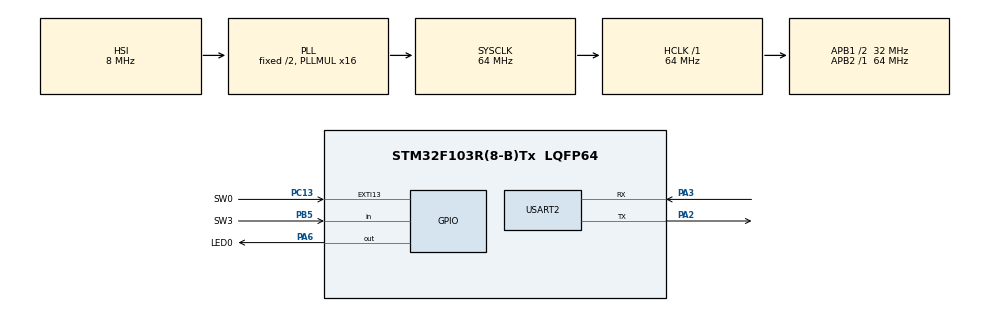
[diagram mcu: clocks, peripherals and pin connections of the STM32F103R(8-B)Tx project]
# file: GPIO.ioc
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Mcu.Family=STM32F1
Mcu.Name=STM32F103R(8-B)Tx
Mcu.Package=LQFP64
NVIC.EXTI15_10_IRQn=true\:0\:0\:false\:false\:true\:true\:true
NVIC.PriorityGroup=NVIC_PRIORITYGROUP_4
PA13.Mode=Serial_Wire
PA13.Signal=SYS_JTMS-SWDIO
PA14.Mode=Serial_Wire
PA14.Signal=SYS_JTCK-SWCLK
PA2.Mode=Asynchronous
PA2.Signal=USART2_TX
PA3.Mode=Asynchronous
PA3.Signal=USART2_RX
PA6.GPIO_Label=LED0
PA6.PinState=GPIO_PIN_RESET
PA6.Signal=GPIO_Output
PB5.GPIO_Label=SW3
PB5.Signal=GPIO_Input
PC13-TAMPER-RTC.GPIO_Label=SW0
PC13-TAMPER-RTC.GPIO_ModeDefaultEXTI=GPIO_MODE_IT_RISING_FALLING
PC13-TAMPER-RTC.Signal=GPXTI13
ProjectManager.HeapSize=0x200
ProjectManager.StackSize=0x400
ProjectManager.TargetToolchain=STM32CubeIDE
RCC.AHBFreq_Value=64000000
RCC.APB1CLKDivider=RCC_HCLK_DIV2
RCC.APB1Freq_Value=32000000
RCC.APB1TimFreq_Value=64000000
RCC.APB2Freq_Value=64000000
RCC.APB2TimFreq_Value=64000000
RCC.HCLKFreq_Value=64000000
RCC.PLLMUL=RCC_PLL_MUL16
RCC.SYSCLKFreq_VALUE=64000000
RCC.SYSCLKSource=RCC_SYSCLKSOURCE_PLLCLK
RCC.USBFreq_Value=64000000
USART2.VirtualMode=VM_ASYNC
board=custom

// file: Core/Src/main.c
/* USER CODE BEGIN Header */
/**
  ******************************************************************************
  * @file           : main.c
  * @brief          : Main program body
  ******************************************************************************
  * @attention
  *
  * <h2><center>&copy; Copyright (c) 2021 STMicroelectronics.
  * All rights reserved.</center></h2>
  *
  * This software component is licensed by ST under BSD 3-Clause license,
  * the "License"; You may not use this file except in compliance with the
  * License. You may obtain a copy of the License at:
  *                        opensource.org/licenses/BSD-3-Clause
  *
  ******************************************************************************
  */
/* USER CODE END Header */
#include "main.h"

UART_HandleTypeDef huart2;

void SystemClock_Config(void);
static void MX_GPIO_Init(void);
static void MX_USART2_UART_Init(void);

int main(void)
{

  /* MCU Configuration--------------------------------------------------------*/

  /* Reset of all peripherals, Initializes the Flash interface and the Systick. */
  HAL_Init();

  /* Configure the system clock */
  SystemClock_Config();

  /* Initialize all configured peripherals */
  MX_GPIO_Init();
  MX_USART2_UART_Init();

  /* Infinite loop */
  /* USER CODE BEGIN WHILE */
  while (1)
  {
	  //HAL_GPIO_WritePin (LED0_GPIO_Port, LED0_Pin, GPIO_PIN_SET);
/*

*/
    /* USER CODE END WHILE */

  }
}

void SystemClock_Config(void)
{
  RCC_OscInitTypeDef RCC_OscInitStruct = {0};
  RCC_ClkInitTypeDef RCC_ClkInitStruct = {0};

  /** Initializes the RCC Oscillators according to the specified parameters
  * in the RCC_OscInitTypeDef structure.
  */
  RCC_OscInitStruct.OscillatorType = RCC_OSCILLATORTYPE_HSI;
  RCC_OscInitStruct.HSIState = RCC_HSI_ON;
  RCC_OscInitStruct.HSICalibrationValue = RCC_HSICALIBRATION_DEFAULT;
  RCC_OscInitStruct.PLL.PLLState = RCC_PLL_ON;
  RCC_OscInitStruct.PLL.PLLSource = RCC_PLLSOURCE_HSI_DIV2;
  RCC_OscInitStruct.PLL.PLLMUL = RCC_PLL_MUL16;
  if (HAL_RCC_OscConfig(&RCC_OscInitStruct) != HAL_OK)
  {
    Error_Handler();
  }
  /** Initializes the CPU, AHB and APB buses clocks
  */
  RCC_ClkInitStruct.ClockType = RCC_CLOCKTYPE_HCLK|RCC_CLOCKTYPE_SYSCLK
                              |RCC_CLOCKTYPE_PCLK1|RCC_CLOCKTYPE_PCLK2;
  RCC_ClkInitStruct.SYSCLKSource = RCC_SYSCLKSOURCE_PLLCLK;
  RCC_ClkInitStruct.AHBCLKDivider = RCC_SYSCLK_DIV1;
  RCC_ClkInitStruct.APB1CLKDivider = RCC_HCLK_DIV2;
  RCC_ClkInitStruct.APB2CLKDivider = RCC_HCLK_DIV1;

  if (HAL_RCC_ClockConfig(&RCC_ClkInitStruct, FLASH_LATENCY_2) != HAL_OK)
  {
    Error_Handler();
  }
}

static void MX_USART2_UART_Init(void)
{

  huart2.Instance = USART2;
  huart2.Init.BaudRate = 115200;
  huart2.Init.WordLength = UART_WORDLENGTH_8B;
  huart2.Init.StopBits = UART_STOPBITS_1;
  huart2.Init.Parity = UART_PARITY_NONE;
  huart2.Init.Mode = UART_MODE_TX_RX;
  huart2.Init.HwFlowCtl = UART_HWCONTROL_NONE;
  huart2.Init.OverSampling = UART_OVERSAMPLING_16;
  if (HAL_UART_Init(&huart2) != HAL_OK)
  {
    Error_Handler();
  }

}

static void MX_GPIO_Init(void)
{
  GPIO_InitTypeDef GPIO_InitStruct = {0};

  /* GPIO Ports Clock Enable */
  __HAL_RCC_GPIOC_CLK_ENABLE();
  __HAL_RCC_GPIOA_CLK_ENABLE();
  __HAL_RCC_GPIOB_CLK_ENABLE();

  /*Configure GPIO pin Output Level */
  HAL_GPIO_WritePin(LED0_GPIO_Port, LED0_Pin, GPIO_PIN_RESET);

  /*Configure GPIO pin : SW0_Pin */
  GPIO_InitStruct.Pin = SW0_Pin;
  GPIO_InitStruct.Mode = GPIO_MODE_IT_RISING_FALLING;
  GPIO_InitStruct.Pull = GPIO_NOPULL;
  HAL_GPIO_Init(SW0_GPIO_Port, &GPIO_InitStruct);

  /*Configure GPIO pin : LED0_Pin */
  GPIO_InitStruct.Pin = LED0_Pin;
  GPIO_InitStruct.Mode = GPIO_MODE_OUTPUT_PP;
  GPIO_InitStruct.Pull = GPIO_NOPULL;
  GPIO_InitStruct.Speed = GPIO_SPEED_FREQ_LOW;
  HAL_GPIO_Init(LED0_GPIO_Port, &GPIO_InitStruct);

  /*Configure GPIO pin : SW3_Pin */
  GPIO_InitStruct.Pin = SW3_Pin;
  GPIO_InitStruct.Mode = GPIO_MODE_INPUT;
  GPIO_InitStruct.Pull = GPIO_NOPULL;
  HAL_GPIO_Init(SW3_GPIO_Port, &GPIO_InitStruct);

  /* EXTI interrupt init*/
  HAL_NVIC_SetPriority(EXTI15_10_IRQn, 0, 0);
  HAL_NVIC_EnableIRQ(EXTI15_10_IRQn);

}

/* USER CODE BEGIN 4 */
void HAL_GPIO_EXTI_Callback(uint16_t GPIO_Pin)
{
	switch(GPIO_Pin)
	{
		case GPIO_PIN_13:
			if (HAL_GPIO_ReadPin (SW0_GPIO_Port, SW0_Pin))
				HAL_GPIO_WritePin (LED0_GPIO_Port, LED0_Pin, GPIO_PIN_SET);
			else
				HAL_GPIO_WritePin (LED0_GPIO_Port, LED0_Pin, GPIO_PIN_RESET);
			break;
	}
}

/* USER CODE END 4 */

void Error_Handler(void)
{
  __disable_irq();
  while (1)
  {
  }
}

/************************ (C) COPYRIGHT STMicroelectronics *****END OF FILE****/
